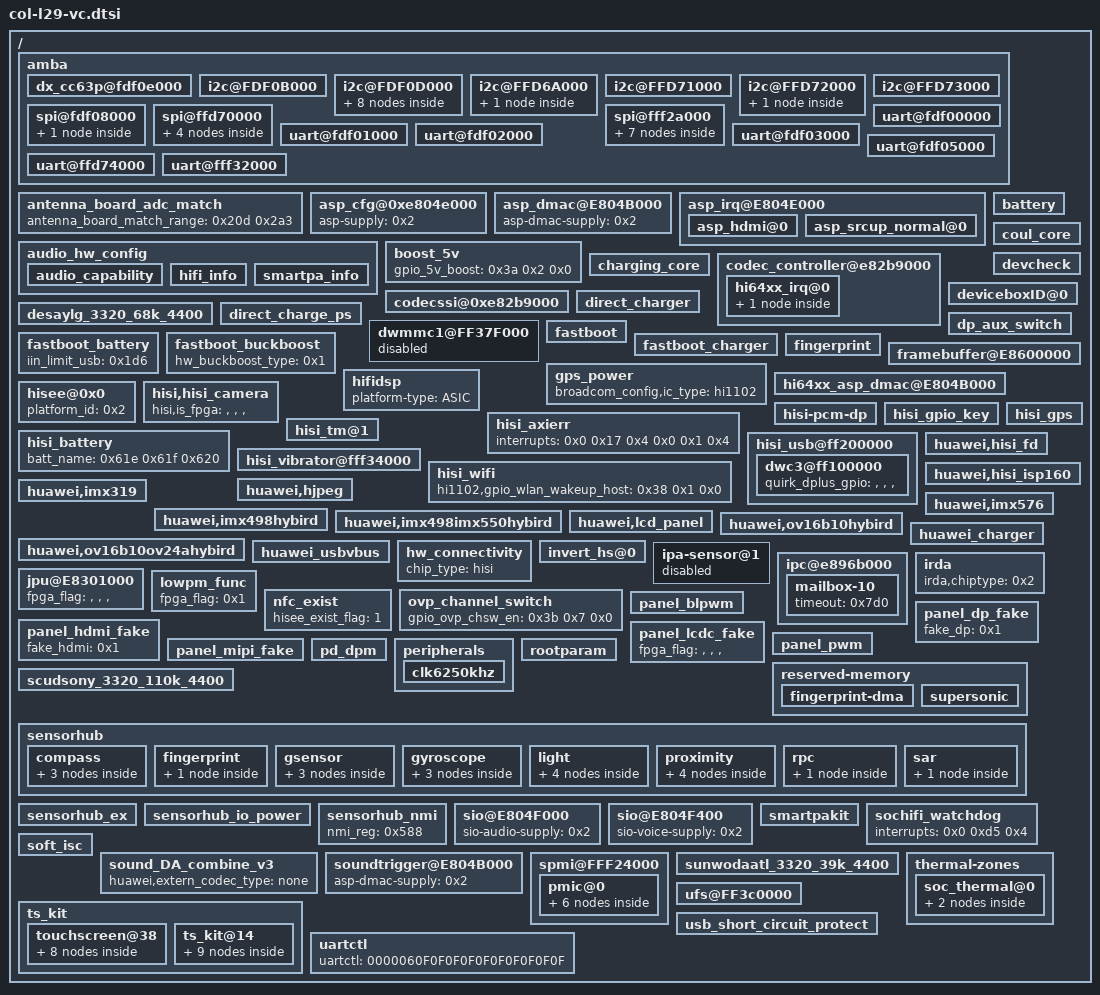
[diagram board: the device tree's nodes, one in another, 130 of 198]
// SPDX-License-Identifier: GPL-2.0
// Editable settings imported from col-l29-vc.dtbo.
/ {
	amba {
		dx_cc63p@fdf0e000 {
			interrupt-parent = <0x1>;
			interrupts = <0x0 0x87 0x4>;
		};
		i2c@FDF0B000 {
			clock-rate = <0x0 0x69db9c0>;
			cs-gpios = <0x232 0x6 0x0 0x232 0x7 0x0>;
			pinctrl-0 = <0x321 0x323 0x409 0x40b>;
			pinctrl-1 = <0x322 0x324 0x40a 0x40c>;
			pinctrl-names = "default", "idle";
		};
		i2c@FDF0D000 {
			ak4376@10 {
				ak4376,hifi_pdn = <0x38 0x7 0x0>;
				ak4376,swtich_existence = "", "", "", "";
				status = "ok";
			};
			huawei,aw3642@7F {
				huawei,flash-chipid = <0x36>;
				huawei,flash-index = "", "", "", "";
				huawei,flash-type = "", "", "", "";
				huawei,flash_current = <0x1f>;
				huawei,slave-address = <0x7f>;
				huawei,torch_current = <0x17>;
			};
			huawei,lm3642@63 {
				huawei,flash-chipid = "", "", "", "";
				huawei,flash-index = "", "", "", "";
				huawei,flash-type = "", "", "", "";
				huawei,flash_current = <0x7>;
				huawei,slave-address = <0x63>;
				huawei,torch_current = <0x2>;
			};
			huawei,mp3331@67 {
				huawei,flash-chipid = <0x18>;
				huawei,flash-index = "", "", "", "";
				huawei,flash-type = "", "", "", "";
				huawei,flash_current = <0x18>;
				huawei,slave-address = <0x67>;
				huawei,torch_current = <0x5>;
			};
			smartpa@4C {
				chip_id = "", "", "", "";
				chip_model = "tas2560";
				chip_vendor = <0x2>;
				compatible = "huawei,smartpakit_i2c";
				dump_regs = <0x0 0x0 0x1 0x0 0x80 0x0 0x0 0x32 0x1 0x0 0x80 0x0 0x0 0x33 0x1 0x0 0x80 0x0 0x0 0x34 0x1 0x0 0x80 0x0>;
				reset_debounce_wait_time = <0x64>;
				version_regs = <0x0 0x0 0x1 0x7d 0x1 0x0>;
				hw_reset {
					ctl_sequence = <0x0 0x3 0x1 0x2>;
					gpio_reset = <0x86>;
				};
				irq_handler {
					gpio_irq = <0xc8>;
					irq_flags = <0x2>;
					need_reset;
					rw_sequence = <0x0 0x14 0x2 0x0 0x0 0x1 0x25 0x1 0x0 0x26 0x1 0x0 0x27 0x1 0x0 0x7 0x1 0x0 0x2a 0x1 0x0>;
				};
				regmap_cfg {
					cache_type = "", "", "", "";
					max_register = <0x80>;
					reg_bits = <0x8>;
					val_bits = <0x8>;
				};
			};
		};
		i2c@FFD6A000 {
			hi6523_charger_i2c6@6B {
				bat_comp = <0x1e>;
				fcp_support = <0x1>;
				gpio_int = <0x5a 0x6 0x0>;
				ico_current_mode = "", "", "", "";
				scp_support = <0x1>;
				vclamp = <0x64>;
			};
		};
		i2c@FFD71000 {
			pinctrl-0;
			pinctrl-1;
			pinctrl-names = "default", "idle";
		};
		i2c@FFD72000 {
			clock-rate = <0x0 0x200b200>;
			cs-gpios = <0x232 0x4 0x0 0x232 0x5 0x0>;
			pinctrl-0 = <0x31d 0x31f 0x405 0x407>;
			pinctrl-1 = <0x31e 0x320 0x406 0x408>;
			pinctrl-names = "default", "idle";
			rt9748@67 {
				loadswitch_en = <0x2a 0x2 0x0>;
				loadswitch_int = <0x2c 0x3 0x0>;
				status = "ok";
			};
		};
		i2c@FFD73000 {
			clock-rate = <0x0 0x200b200>;
			cs-gpios = <0x232 0x6 0x0 0x232 0x7 0x0>;
			pinctrl-0 = <0x321 0x323 0x409 0x40b>;
			pinctrl-1 = <0x322 0x324 0x40a 0x40c>;
			pinctrl-names = "default", "idle";
		};
		spi@fdf08000 {
			clock-rate = <0x124f800>;
			pinctrl-0 = <0x285 0x287 0x289 0x368 0x36a 0x36c>;
			pinctrl-1 = <0x286 0x288 0x28a 0x369 0x36b 0x36d>;
			pinctrl-names = "default", "idle";
			spi_dev10@10 {
				pl022,com-mode = "", "", "", "";
				pl022,ctrl-len = <0x7>;
				pl022,duplex = "", "", "", "";
				pl022,interface = "", "", "", "";
				pl022,rx-level-trig = <0x3>;
				pl022,slave-tx-disable = "", "", "", "";
				pl022,tx-level-trig = <0x3>;
				pl022,wait-state = "", "", "", "";
				reg = "", "", "", "";
				spi-max-frequency = <0x186a0>;
			};
		};
		spi@ffd70000 {
			clock-rate = <0x0 0x802c800>;
			hardware-mutex = <0x1>;
			spi_dev0@0 {
				pl022,com-mode = "", "", "", "";
				pl022,ctrl-len = <0x7>;
				pl022,duplex = "", "", "", "";
				pl022,interface = "", "", "", "";
				pl022,rx-level-trig = <0x3>;
				pl022,slave-tx-disable = "", "", "", "";
				pl022,tx-level-trig = <0x3>;
				pl022,wait-state = "", "", "", "";
				spi-max-frequency = <0x186a0>;
			};
			spi_dev1@1 {
				pl022,com-mode = <0x1>;
				pl022,ctrl-len = <0x7>;
				pl022,duplex = "", "", "", "";
				pl022,interface = "", "", "", "";
				pl022,rx-level-trig = <0x3>;
				pl022,slave-tx-disable = "", "", "", "";
				pl022,tx-level-trig = <0x3>;
				pl022,wait-state = "", "", "", "";
				reg = <0x1>;
				spi-max-frequency = <0xc65d40>;
			};
			spi_dev2@2 {
				pl022,com-mode = <0x2>;
				pl022,ctrl-len = <0x7>;
				pl022,duplex = "", "", "", "";
				pl022,interface = "", "", "", "";
				pl022,rx-level-trig = <0x3>;
				pl022,slave-tx-disable = "", "", "", "";
				pl022,tx-level-trig = <0x3>;
				pl022,wait-state = "", "", "", "";
				reg = <0x2>;
				spi-max-frequency = <0xc65d40>;
			};
			spi_dev3@3 {
				pl022,com-mode = "", "", "", "";
				pl022,ctrl-len = <0x7>;
				pl022,duplex = "", "", "", "";
				pl022,interface = "", "", "", "";
				pl022,rx-level-trig = <0x3>;
				pl022,slave-tx-disable = "", "", "", "";
				pl022,tx-level-trig = <0x3>;
				pl022,wait-state = "", "", "", "";
				reg = <0x3>;
				spi-max-frequency = <0xc65d40>;
			};
		};
		spi@fff2a000 {
			huawei_thp@10 {
				boot_reset_after_delay_ms = "", "", "", "";
				boot_reset_hi_delay_ms = <0x1>;
				boot_reset_low_delay_ms = "", "", "", "";
				cs_gpio = <0x5a 0x3 0x0>;
				irq_gpio = <0x2b 0x4 0x0>;
				pl022,com-mode = <0x2>;
				pl022,ctrl-len = <0x7>;
				pl022,duplex = "", "", "", "";
				pl022,interface = "", "", "", "";
				pl022,rx-level-trig = <0x3>;
				pl022,slave-tx-disable = "", "", "", "";
				pl022,tx-level-trig = <0x3>;
				pl022,wait-state = "", "", "", "";
				reg = "", "", "", "";
				resume_reset_after_delay_ms = <0x1>;
				rst_gpio = <0x50 0x7 0x0>;
				spi-bus-id = <0x3>;
				spi-max-frequency = <0x989680>;
				spi_sync_cs_hi_delay_ns = <0xc8>;
				spi_sync_cs_low_delay_ns = <0xa>;
				suspend_reset_after_delay_ms = "", "", "", "";
				novatech {
					spi_sync_cs_hi_delay_ns = <0xc8>;
					spi_sync_cs_low_delay_ns = <0xc8>;
				};
				thp_input_dev {
					abs_max_x = <0x5a0>;
					abs_max_y = <0xa00>;
					compatible = "huawei,thp_input";
				};
			};
			spi_dev30@30 {
				pl022,com-mode = "", "", "", "";
				pl022,ctrl-len = <0x7>;
				pl022,duplex = "", "", "", "";
				pl022,interface = "", "", "", "";
				pl022,rx-level-trig = <0x3>;
				pl022,slave-tx-disable = "", "", "", "";
				pl022,tx-level-trig = <0x3>;
				pl022,wait-state = "", "", "", "";
				reg = "", "", "", "";
				spi-max-frequency = <0x186a0>;
			};
			spi_dev31@31 {
				pl022,com-mode = <0x1>;
				pl022,ctrl-len = <0x7>;
				pl022,duplex = "", "", "", "";
				pl022,interface = "", "", "", "";
				pl022,rx-level-trig = <0x3>;
				pl022,slave-tx-disable = "", "", "", "";
				pl022,tx-level-trig = <0x3>;
				pl022,wait-state = "", "", "", "";
				reg = <0x1>;
				spi-max-frequency = <0xc65d40>;
			};
			spi_dev32@32 {
				pl022,com-mode = <0x2>;
				pl022,ctrl-len = <0x7>;
				pl022,duplex = "", "", "", "";
				pl022,interface = "", "", "", "";
				pl022,rx-level-trig = <0x3>;
				pl022,slave-tx-disable = "", "", "", "";
				pl022,tx-level-trig = <0x3>;
				pl022,wait-state = "", "", "", "";
				reg = <0x2>;
				spi-max-frequency = <0xc65d40>;
			};
			spi_dev33@33 {
				pl022,com-mode = "", "", "", "";
				pl022,ctrl-len = <0x7>;
				pl022,duplex = "", "", "", "";
				pl022,interface = "", "", "", "";
				pl022,rx-level-trig = <0x3>;
				pl022,slave-tx-disable = "", "", "", "";
				pl022,tx-level-trig = <0x3>;
				pl022,wait-state = "", "", "", "";
				reg = <0x3>;
				spi-max-frequency = <0xc65d40>;
			};
		};
		uart@fdf00000 {
			clock-rate = <0x0 0x69db9c0>;
			pinctrl-0;
			pinctrl-1;
			pinctrl-names = "default", "idle";
			reset-enable-flag = <0x1>;
		};
		uart@fdf01000 {
			clock-rate = <0x0 0x69db9c0>;
			pinctrl-0 = <0x2bf 0x2c1 0x2c3 0x2c5 0x3a2 0x3a4 0x3a6 0x3a8>;
			pinctrl-1 = <0x2c0 0x2c2 0x2c4 0x2c6 0x3a3 0x3a5 0x3a7 0x3a9>;
			pinctrl-names = "default", "idle";
			reset-enable-flag = <0x1>;
		};
		uart@fdf02000 {
			clock-rate = <0x0 0x124f800>;
			dma-names = "", "";
			dmas;
			pinctrl-0 = <0x2b1 0x2b3 0x394 0x396>;
			pinctrl-1 = <0x2b2 0x2b4 0x395 0x397>;
			pinctrl-names = "default", "idle";
		};
		uart@fdf03000 {
			clock-rate = <0x0 0x69db9c0>;
			pinctrl-0;
			pinctrl-1;
			pinctrl-names = "default", "idle";
			reset-enable-flag = <0x1>;
		};
		uart@fdf05000 {
			clock-rate = <0x0 0x69db9c0>;
			pinctrl-0 = <0x2b9 0x3c 0x2bb 0x2bd 0x39c 0x3f 0x39e 0x3a0>;
			pinctrl-1 = <0x2ba 0x41 0x2bc 0x2be 0x39d 0x44 0x39f 0x3a1>;
			pinctrl-names = "default", "idle";
			reset-enable-flag = <0x1>;
		};
		uart@ffd74000 {
			clock-rate = <0x0 0x5f5e100>;
			pinctrl-0;
			pinctrl-1;
			pinctrl-names = "default", "idle";
		};
		uart@fff32000 {
			clock-rate = <0x0 0x124f800>;
			console-fifo-cpuon = <0x3>;
			console-fifo-enable = <0x1>;
			console-fifo-size = <0x40000>;
			pinctrl-0 = <0x2b5 0x2b7 0x398 0x39a>;
			pinctrl-1 = <0x2b6 0x2b8 0x399 0x39b>;
			pinctrl-names = "default", "idle";
		};
	};
	antenna_board_adc_match {
		antenna_board_match_range = <0x20d 0x2a3>;
	};
	asp_cfg@0xe804e000 {
		asp-supply = <0x2>;
	};
	asp_dmac@E804B000 {
		asp-dmac-supply = <0x2>;
	};
	asp_irq@E804E000 {
		asp_hdmi@0 {
			interrupt-names = "asp_irq_hdmi";
			interrupt-parent = <0x254>;
			interrupts = "", "", "", "", "", "", "", "";
		};
		asp_srcup_normal@0 {
			asp-srcup-normal-supply = <0x2>;
			interrupt-names = "asp_srcup_normal";
			interrupt-parent = <0x254>;
			interrupts = <0x1 0x0>;
		};
	};
	audio_hw_config {
		analog_earpiece_enable = "false";
		audio_sar_support = "true";
		codec_dsp_algo = "mad";
		codec_name = "DA_combine_v3";
		cust_name = "audio_custom";
		karaoke_mic_conf_support = "true";
		product_name = "COL-Oversea";
		spk_pa_name = "smartpakit";
		vqm_enable = "true";
		audio_capability {
			lvm_support = "false";
			mmi_capture_enable = "false";
			wakeup_internal_engine = "false";
		};
		hifi_info {
			dynamic_samplerate_support = "false";
			extern_headset_hifi_enable = "false";
			hifi_chip_type = "none";
			highperform_lowpower_support = "false";
		};
		smartpa_info {
			status = "ok";
		};
	};
	battery {
		battery_board_type = <0x2>;
		battery_design_fcc = <0xd48>;
	};
	boost_5v {
		gpio_5v_boost = <0x3a 0x2 0x0>;
		status = "ok";
	};
	charging_core {
		ichg_ac = <0x834>;
		ichg_fcp = <0xd48>;
		iin_fcp = <0x7d0>;
		iin_usb = <0x1d6>;
		inductance_para = "-32767", "15", "2000", "0", "15", "32767", "2000", "0";
		iterm = <0x88>;
		iterm_para = "scudsony", "160";
	};
	codec_controller@e82b9000 {
		gpios = <0x5a 0x4 0x0>;
		pm_runtime_support;
		hi64xx_irq@0 {
			hi6403_codec@0 {
				extern_hs_hifi_ak4376_I2S3 = "", "", "", "";
				hi6421_0x109_reg_change = "", "", "", "";
				hi6421_0x109_xo_freq_codec_val = <0x1>;
				hisilicon,hs_4_pole_min_voltage = <0x384>;
				hisilicon,hs_extern_cable_max_voltage = <0xa8c>;
				hisilicon,hs_extern_cable_min_voltage = <0xa5b>;
				hisilicon,wakeup_audio_algo_support = "", "", "", "";
				hs_detect_extern_cable = <0x1>;
			};
		};
	};
	codecssi@0xe82b9000 {
		status = "ok";
	};
	coul_core {
		adc_batt_id = <0xb>;
		adc_batt_temp = <0xa>;
		current_full_enable = <0x1>;
		iscd_enable = <0x1>;
		last_soc_enable = <0x1>;
		normal_cutoff_vol_mv = <0xbb8>;
		r_coul_mohm = <0x5>;
		r_pcb = "", "", "", "";
		soc_at_term = <0x62>;
	};
	desaylg_3320_68k_4400 {
		fcc_temp = <0xcd0 0xcd0 0xcd0 0xcd0 0xcd0 0xcd0>;
		ifull = <0x12c>;
	};
	devcheck {
		charge = <0x3>;
		charge_loadswitch = <0x3>;
		compass = <0x3>;
		dc_dc = <0x3>;
		g_sensor = <0x3>;
		gyroscope = <0x3>;
		l_sensor = <0x2>;
		nfc = <0x3>;
		touch_panel = <0x2>;
		tps = <0x3>;
	};
	deviceboxID@0 {
		box_num = <0x1>;
		check_mode = "gpio";
		deviceboxID_limit = <0x1f4>;
		enable_boxID = <0x1 0x0 0x0 0x0>;
		gpio_num = <0x1 0x0 0x0 0x0>;
		gpio_speakerID = <0x4b8 0x1 0x0>;
		pinctrl-0 = <0x44d 0x456>;
		pinctrl-1 = <0x44e 0x457>;
		pinctrl-names = "default", "idle";
		speaker_map = <0x1 0x2>;
	};
	direct_charge_ps {
		boost_5v_support_scp_power = <0x1>;
		bst_ctrl = <0x2c 0x4 0x0>;
		bst_ctrl_use_common_gpio = "", "", "", "";
		is_need_bst_ctrl = <0x1>;
	};
	direct_charger {
		cc_cable_detect_enable = <0x1>;
		compensate_r = <0x14>;
		full_path_res_max = <0x1f4>;
		resist_para = "0", "250", "4000", "250", "300", "3000", "300", "500", "2000";
		scp_work_on_charger = <0x1>;
		standard_cable_full_path_res_max = <0x1f4>;
		std_resist_para = "0", "250", "4500", "250", "300", "4000", "300", "500", "3000";
		temp_para = "-32767", "10", "0", "10", "45", "4500", "45", "32767", "0";
		use_5A = <0x1>;
		volt_para = "4100", "4500", "4100", "4250", "4100", "2400", "4380", "2400", "1000";
	};
	dp_aux_switch {
		cs-gpios = <0x50 0x1 0x0 0x50 0x2 0x0>;
		pinctrl-0 = <0x287 0x289 0x36a 0x36c>;
		pinctrl-1 = <0x288 0x28a 0x36b 0x36d>;
		pinctrl-names = "default", "idle";
	};
	dwmmc1@FF37F000 {
		cd-gpio = <0x3a 0x5 0x0>;
		cd-vol = <0x1>;
		cs_sd_timing_config;
		shared-irq = <0x1>;
		status = "disable";
		vmmc-supply = <0x5cc>;
		vqmmc-supply = <0xc9>;
	};
	fastboot {
		gpio-keydown = <0xe6>;
		gpio-keyup = <0xe7>;
		i2c-sel0-gpio = <0x2c>;
		i2c-sel0-val = "", "", "", "";
		i2c-sel1-gpio = <0x2d>;
		i2c-sel1-val = "", "", "", "";
		i2c-select = <0x1>;
		i2c3-pin = "", "", "", "";
		jtagtosd-board-type = <0x1>;
		lpm3-board-type = <0x2>;
		uart-board-type = <0x1>;
	};
	fastboot_battery {
		iin_limit_usb = <0x1d6>;
	};
	fastboot_buckboost {
		hw_buckboost_type = <0x1>;
	};
	fastboot_charger {
		chip_i2c_num = <0x6>;
		hw_charger_type = <0x4>;
	};
	fingerprint {
		fingerprint,cs_gpio = <0xd8>;
		fingerprint,extern_ldo_name = "EXTERN_LDO";
		fingerprint,extern_ldo_num = <0x15>;
		fingerprint,extern_vol = <0x1c3a90>;
		fingerprint,force_storage_type = <0x1>;
		fingerprint,fpc2050 = <0x1>;
		fingerprint,irq_custom_scheme = <0x1>;
		fingerprint,irq_gpio = <0xd3>;
		fingerprint,navigation_adjust1 = <0x1>;
		fingerprint,navigation_adjust2 = <0xb4>;
		fingerprint,product = "columbia";
		fingerprint,reset_gpio = <0xd2>;
		fingerprint,sensor_type = <0x302>;
		fingerprint,spi_num = <0x2>;
		fingerprint,switch_frequence_support = <0x1>;
		fingreprint_ldo-supply = <0x5cf>;
		pinctrl-names = "default", "idle";
		spi-max-frequency = <0x4c4b40>;
	};
	framebuffer@E8600000 {
		dss_version_tag = <0x40>;
		fpga_flag = "", "", "", "";
	};
	gps_power {
		broadcom_config,ic_type = "hi1102";
	};
	hi64xx_asp_dmac@E804B000 {
		asp-dmac-supply = <0x2>;
		interrupt-names = "asp_dma_irq";
		interrupts = <0x0 0xd8 0x4>;
	};
	hifidsp {
		platform-type = "ASIC";
	};
	hisee@0x0 {
		platform_id = <0x2>;
	};
	hisi,hisi_camera {
		hisi,is_fpga = "", "", "", "";
	};
	hisi-pcm-dp {
		dp-pcm-supply = <0x2>;
		interrupt-names = "asp_hdmi_dma";
		interrupts = <0x0 0x96 0x4>;
	};
	hisi_axierr {
		interrupts = <0x0 0x17 0x4 0x0 0x1 0x4>;
	};
	hisi_battery {
		batt_name = <0x61e 0x61f 0x620>;
	};
	hisi_gpio_key {
		gpio-keydown,gpio-irq = <0x5d 0x6 0x0>;
		gpio-keyup,gpio-irq = <0x5d 0x7 0x0>;
		pinctrl-0 = <0x445 0x443>;
		pinctrl-1 = <0x446 0x444>;
		pinctrl-names = "default", "idle";
	};
	hisi_gps {
		clock-names = "ref_clk", "mux_clk", "mdm_clk0", "mdm_clk1", "mdm_clk2";
		clocks = <0x55c 0x161 0x162 0x163 0x164>;
		pinctrl-0 = <0x283 0x366>;
		pinctrl-1 = <0x284 0x367>;
		pinctrl-names = "default", "idle";
	};
	hisi_tm@1 {
		hisi,detect_charger1_tm_chanel = <0x6>;
		hisi,detect_charger1_tm_state = "enable";
		hisi,detect_flash_led_tm_chanel = <0x3>;
		hisi,detect_flash_led_tm_state = "enable";
		hisi,detect_pa_1_tm_state = "disable";
		hisi,peripheral_sensors = <0x8>;
	};
	hisi_usb@ff200000 {
		eye_diagram_host_param = <0x33de7e7>;
		eye_diagram_param = <0x23de7e7>;
		usb_aclk_freq = <0xe2f9780>;
		usb_support_check_voltage = "", "", "", "";
		usb_support_dp = <0x1>;
		dwc3@ff100000 {
			quirk_dplus_gpio = "", "", "", "";
		};
	};
	hisi_vibrator@fff34000 {
		vibrator-vdd-supply = <0x5d4>;
		vibrator_vout_max_voltage = <0x2ab980>;
		vibrator_vout_min_voltage = <0x2ab980>;
	};
	hisi_wifi {
		hi1102,gpio_wlan_wakeup_host = <0x38 0x1 0x0>;
	};
	huawei,hisi_fd {
		clock-low-frequency = <0x1082af40>;
		clock-names = "clk_fd_func";
		clock-value = <0x11e1a300>;
		clocks = <0x5b3>;
		fd-pwr-seq = "fd_regulator", "fd_clk";
		fd_offset_list = <0x418 0x40c 0x410 0x414 0x464 0xfd 0x7a 0x9f 0x58 0x31c 0x470>;
		hisi-fd-supply = <0x1c5>;
		hisi-media-supply = <0x1cd>;
		huawei,smmu-flag = "", "", "", "";
		huawei,top-base = <0xe8304000 0x1000>;
		interrupts = <0x0 0x133 0x4>;
		mstr_offset_list = <0x28 0x34 0x100 0x260 0x3c0>;
		smmu_offset_list = <0x10 0x1c 0x20 0x204 0x20c 0x220 0x224>;
	};
	huawei,hisi_isp160 {
		hisi,is_fpga = "", "", "", "";
		pinctrl-0 = <0x295 0x297 0x299 0x29b 0x29d 0x29f 0x2a1 0x2a3 0x2a5 0x285 0x281 0x44b 0x28f 0x2ad 0x37a 0x37c 0x37e 0x380 0x382 0x384 0x386 0x388 0x38a 0x368 0x364 0x454 0x372 0x390>;
		pinctrl-1 = <0x296 0x298 0x29a 0x29c 0x29e 0x2a0 0x2a2 0x2a4 0x2a6 0x286 0x282 0x44c 0x290 0x2ae 0x37b 0x37d 0x37f 0x381 0x383 0x385 0x387 0x389 0x38b 0x369 0x365 0x455 0x373 0x391>;
		pinctrl-names = "default", "idle";
	};
	huawei,hjpeg {
		clock-low-frequency = <0x1082af40>;
		clock-names = "clk_jpg_func";
		clock-value = <0x21055e80>;
		clocks = <0x237>;
		hjpeg-media-supply = <0x1cd>;
		hjpeg-srt-supply = <0x1c5>;
		huawei,chip_type = <0x1>;
		huawei,cvdr = "", "", "", "", "", "", "", "", "", "", "", "";
		huawei,cvdr-base = <0xe8302000 0x1000>;
		huawei,hjpeg-base = <0xe8300000 0x1000>;
		huawei,power_control = "", "", "", "";
		huawei,smmu-base = <0xe8320000 0x20000>;
		huawei,smmu_type = <0x1>;
		huawei,stream_id = <0x0 0x4 0x5>;
		huawei,subctrl-base = <0xe8304000 0x4>;
		interrupts = <0x0 0x12b 0x4>;
		power-off-frequency = <0xe2f9780>;
		reg = <0x0 0xe8300000 0x0 0x1000>;
	};
	huawei,imx319 {
		avdd-supply = <0x5cb>;
		clock-names = "clk_isp_snclk1";
		clocks = <0x568>;
		dvdd-supply = <0x5d2>;
		gpios = <0x1d7 0x0 0x0>;
		huawei,csi_index = <0x1>;
		huawei,gpio-ctrl-types = "reset";
		huawei,i2c_index = <0x1>;
		huawei,is_fpga = "", "", "", "";
		huawei,ldo-names = "avdd", "dvdd", "iovdd";
		huawei,mclk = <0x16e3600>;
		huawei,pd_valid = <0x1>;
		huawei,reset_valid = <0x1>;
		huawei,sensor_index = <0x1>;
		huawei,sensor_name = "IMX319";
		huawei,vcmpd_valid = "", "", "", "";
		iovdd-supply = <0xc9>;
	};
	huawei,imx498hybird {
		avdd-supply = <0x5d3>;
		avdd2-supply = <0x5cb>;
		clock-names = "clk_isp_snclk0", "clk_isp_snclk2";
		clocks = <0x567 0x569>;
		dvdd-supply = <0x5cd>;
		dvdd2-supply = <0x5ce>;
		gpios = <0x50 0x5 0x0 0x4b8 0x0 0x0>;
		huawei,csi_index = <0x0 0x2>;
		huawei,gpio-ctrl-types = "reset", "reset2";
		huawei,i2c_index = <0x0 0x2>;
		huawei,is_fpga = "", "", "", "";
		huawei,ldo-names = "avdd", "avdd2", "dvdd", "dvdd2", "vcm", "iovdd";
		huawei,mclk = <0x16e3600>;
		huawei,pd_valid = <0x1>;
		huawei,reset_valid = <0x1>;
		huawei,sensor_index = "", "", "", "";
		huawei,sensor_name = "IMX498HYBIRD";
		huawei,vcmpd_valid = "", "", "", "";
		iovdd-supply = <0xc9>;
		module_type = "", "", "", "";
		vcm-supply = <0x5cc>;
	};
	huawei,imx498imx550hybird {
		avdd-supply = <0x5d3>;
		avdd2-supply = <0x5cb>;
		clock-names = "clk_isp_snclk0", "clk_isp_snclk2";
		clocks = <0x567 0x569>;
		dvdd-supply = <0x5cd>;
		dvdd2-supply = <0x5ce>;
		gpios = <0x50 0x5 0x0 0x4b8 0x0 0x0>;
		huawei,csi_index = <0x0 0x2>;
		huawei,gpio-ctrl-types = "reset", "reset2";
		huawei,i2c_index = <0x0 0x2>;
		huawei,is_fpga = "", "", "", "";
		huawei,ldo-names = "avdd", "avdd2", "dvdd", "dvdd2", "vcm", "iovdd";
		huawei,mclk = <0x16e3600>;
		huawei,pd_valid = <0x1>;
		huawei,reset_valid = <0x1>;
		huawei,sensor_index = "", "", "", "";
		huawei,sensor_name = "IMX498IMX550HYBIRD";
		huawei,vcmpd_valid = "", "", "", "";
		iovdd-supply = <0xc9>;
		module_type = "", "", "", "";
		vcm-supply = <0x5cc>;
	};
	huawei,imx576 {
		avdd-supply = <0x5cb>;
		clock-names = "clk_isp_snclk1";
		clocks = <0x568>;
		dvdd-supply = <0x5d2>;
		gpios = <0x1d7 0x0 0x0>;
		huawei,csi_index = <0x1>;
		huawei,gpio-ctrl-types = "reset";
		huawei,i2c_index = <0x1>;
		huawei,is_fpga = "", "", "", "";
		huawei,ldo-names = "avdd", "dvdd", "iovdd";
		huawei,mclk = <0x16e3600>;
		huawei,pd_valid = <0x1>;
		huawei,reset_valid = <0x1>;
		huawei,sensor_index = <0x1>;
		huawei,sensor_name = "IMX576";
		huawei,vcmpd_valid = "", "", "", "";
		iovdd-supply = <0xc9>;
	};
	huawei,lcd_panel {
		lcd-bl-common-ic-support = <0x1>;
		lcd_ldo_channel = <0x2>;
		lcd_ldo_name = "LDO4";
		lcd_ldo_threshold = <0x1388>;
	};
	huawei,ov16b10hybird {
		avdd-supply = <0x5d3>;
		avdd2-supply = <0x5cb>;
		clock-names = "clk_isp_snclk0", "clk_isp_snclk2";
		clocks = <0x567 0x569>;
		dvdd-supply = <0x5cd>;
		dvdd2-supply = <0x5ce>;
		gpios = <0x50 0x5 0x0 0x4b8 0x0 0x0>;
		huawei,csi_index = <0x0 0x2>;
		huawei,gpio-ctrl-types = "reset", "reset2";
		huawei,i2c_index = <0x0 0x2>;
		huawei,is_fpga = "", "", "", "";
		huawei,ldo-names = "avdd", "avdd2", "dvdd", "dvdd2", "vcm", "iovdd";
		huawei,mclk = <0x16e3600>;
		huawei,pd_valid = <0x1>;
		huawei,reset_valid = <0x1>;
		huawei,sensor_index = "", "", "", "";
		huawei,sensor_name = "OV16B10HYBIRD";
		huawei,vcmpd_valid = "", "", "", "";
		iovdd-supply = <0xc9>;
		module_type = "", "", "", "";
		vcm-supply = <0x5cc>;
	};
	huawei,ov16b10ov24ahybird {
		avdd-supply = <0x5d3>;
		avdd2-supply = <0x5cb>;
		clock-names = "clk_isp_snclk0", "clk_isp_snclk2";
		clocks = <0x567 0x569>;
		dvdd-supply = <0x5cd>;
		dvdd2-supply = <0x5ce>;
		gpios = <0x50 0x5 0x0 0x4b8 0x0 0x0>;
		huawei,csi_index = <0x0 0x2>;
		huawei,gpio-ctrl-types = "reset", "reset2";
		huawei,i2c_index = <0x0 0x2>;
		huawei,is_fpga = "", "", "", "";
		huawei,ldo-names = "avdd", "avdd2", "dvdd", "dvdd2", "vcm", "iovdd";
		huawei,mclk = <0x16e3600>;
		huawei,pd_valid = <0x1>;
		huawei,reset_valid = <0x1>;
		huawei,sensor_index = "", "", "", "";
		huawei,sensor_name = "OV16B10OV24AHYBIRD";
		huawei,vcmpd_valid = "", "", "", "";
		iovdd-supply = <0xc9>;
		module_type = "", "", "", "";
		vcm-supply = <0x5cc>;
	};
	huawei_charger {
		fcp_vindpm = <0x1fa4>;
		leak_current_check = <0x1>;
		pd_support = <0x1>;
		support_usb_nonstandard_ico = <0x1>;
	};
	huawei_usbvbus {
		enable_wired_channel = <0x1>;
		pmic_vbus_attach_enable = "", "", "", "";
		pmic_vbus_enable = <0x1>;
	};
	hw_connectivity {
		chip_type = "hisi";
	};
	invert_hs@0 {
		gpio_type = "", "", "", "";
		gpios = "", "", "", "+", "", "", "", "", "", "", "";
		pinctrl-0 = <0x339 0x421>;
		pinctrl-1 = <0x33a 0x422>;
		pinctrl-names = "default", "idle";
	};
	ipa-sensor@1 {
		status = "disabled";
	};
	ipc@e896b000 {
		mailbox-10 {
			timeout = <0x7d0>;
		};
	};
	irda {
		irda,chiptype = <0x2>;
	};
	jpu@E8301000 {
		fpga_flag = "", "", "", "";
	};
	lowpm_func {
		fpga_flag = <0x1>;
	};
	nfc_exist {
		hisee_exist_flag = "1";
	};
	ovp_channel_switch {
		gpio_ovp_chsw_en = <0x3b 0x7 0x0>;
	};
	panel_blpwm {
		#address-cells = <0x2>;
		#size-cells = <0x2>;
		clock-names = "clk_blpwm";
		clocks = <0x5a3>;
		fpga_flag = "", "", "", "";
		pinctrl-0 = <0x315 0x317 0x3fd 0x3ff>;
		pinctrl-1 = <0x316 0x318 0x3fe 0x400>;
		pinctrl-names = "default", "idle";
	};
	panel_dp_fake {
		fake_dp = <0x1>;
	};
	panel_hdmi_fake {
		fake_hdmi = <0x1>;
	};
	panel_lcdc_fake {
		#address-cells = <0x2>;
		#size-cells = <0x2>;
		fpga_flag = "", "", "", "";
	};
	panel_mipi_fake {
		#address-cells = <0x2>;
		#size-cells = <0x2>;
		bl_enable_flag = "", "", "", "";
		fpga_flag = "", "", "", "";
		gpio_nums = <0x22 0x33 0xc>;
		gpios = <0x1d7 0x2 0x0 0x5b 0x3 0x0 0x50 0x4 0x0>;
		lcd-bl-ic-name = "LM36923YFFR";
	};
	panel_pwm {
		#address-cells = <0x2>;
		#size-cells = <0x2>;
		clock-names = "clk_pwm";
		clocks = <0x55b>;
		fpga_flag = "", "", "", "";
	};
	pd_dpm {
		abnormal_cc_detection = <0x1>;
		support_dp = "", "", "", "";
	};
	peripherals {
		clk6250khz {
			#clock-cells = "", "", "", "";
			clock-frequency = <0x601800>;
			clock-output-names = "clk6250khz";
		};
	};
	reserved-memory {
		fingerprint-dma {
			status = "ok";
		};
		supersonic {
			status = "ok";
		};
	};
	rootparam {
		hisi,boardid = <0x6 0x8 0x2 0x3>;
		hisi,boardname = "COL_L29_VC";
		hisi,dtbo_idx = <0x64>;
	};
	scudsony_3320_110k_4400 {
		fcc_temp = <0xcd0 0xcd0 0xcd0 0xcd0 0xcd0 0xcd0>;
		ifull = <0x12c>;
	};
	sensorhub {
		compass {
			mag1 {
				fifoMaxEventCount = "", "", "", "";
				fifoReservedEventCount = "", "", "", "";
				file_id = <0x25>;
				minDelay = <0x2710>;
				sensorlist_name = "mag-akm09911";
				softfilter = <0x2>;
				softiron_parameter = <0xb8 0x28 0x3b 0xff 0xa8 0xff 0x77 0x0 0xad 0x27 0x8e 0xff 0x4f 0x1 0x99 0x0 0x45 0x26 0x0 0x0 0x0 0x0 0x0 0x0 0x0 0x0 0x0>;
				threshold_for_als_calibrate = <0xdac>;
				vendor = "akm";
			};
			mag2 {
				axis_map_x = <0x1>;
				axis_map_y = "", "", "", "";
				axis_map_z = <0x2>;
				bus_number = "", "", "", "";
				calibrate_method = <0x2>;
				chip_id_register = <0x80>;
				chip_id_value = <0x7>;
				fifoMaxEventCount = "", "", "", "";
				fifoReservedEventCount = "", "", "", "";
				file_id = <0x42>;
				gpio_int1 = "", "", "", "7", "", "", "", "", "", "", "";
				gpio_reset = "", "", "", "7", "", "", "", "", "", "", "";
				minDelay = <0x2710>;
				negate_x = "", "", "", "";
				negate_y = "", "", "", "";
				negate_z = <0x1>;
				outbit = "", "", "", "";
				poll_interval = <0xa>;
				reg = <0x2e>;
				sensor_list_info_id = <0x1>;
				sensor_type = "mag";
				sensorlist_name = "mag-yas537";
				softfilter = <0x2>;
				softiron_parameter = <0x10 0x27 0x0 0x0 0x0 0x0 0x0 0x0 0x10 0x27 0x0 0x0 0x0 0x0 0x0 0x0 0x10 0x27 0x0 0x0 0x0 0x0 0x0 0x0 0x0 0x0 0x0>;
				threshold_for_als_calibrate = <0x7d0>;
				vendor = "yamaha";
			};
			mag3 {
				axis_map_x = <0x1>;
				axis_map_y = "", "", "", "";
				axis_map_z = <0x2>;
				bus_number = "", "", "", "";
				calibrate_method = <0x2>;
				chip_id_register = "", "", "", "";
				chip_id_value = <0x48>;
				fifoMaxEventCount = "", "", "", "";
				fifoReservedEventCount = "", "", "", "";
				file_id = <0x43>;
				gpio_int1 = "", "", "", "7", "", "", "", "", "", "", "";
				gpio_reset = "", "", "", "7", "", "", "", "", "", "", "";
				minDelay = <0x2710>;
				negate_x = "", "", "", "";
				negate_y = "", "", "", "";
				negate_z = <0x1>;
				outbit = "", "", "", "";
				poll_interval = <0xa>;
				reg = <0xc>;
				sensor_list_info_id = <0x1>;
				sensor_type = "mag";
				sensorlist_name = "akm-akm09918";
				softiron_parameter = <0xb8 0x28 0x3b 0xff 0xa8 0xff 0x77 0x0 0xad 0x27 0x8e 0xff 0x4f 0x1 0x99 0x0 0x45 0x26 0x0 0x0 0x0 0x0 0x0 0x0 0x0 0x0 0x0>;
				threshold_for_als_calibrate = <0xdac>;
				vendor = "akm";
			};
		};
		fingerprint {
			finger1 {
				bus_number = <0x2>;
				bus_type = <0x1>;
				chip_id_register = <0xaa>;
				chip_id_value = <0x1500>;
				combo_bus_num = <0x2>;
				combo_bus_type = "spi";
				combo_data = <0xd8>;
				combo_rx_exp = [02 15];
				combo_rx_mask = [ff ff];
				combo_tx = [aa];
				file_id = <0x5a>;
				gpio_cs = <0xd8>;
				gpio_irq = <0xd3>;
				gpio_irq_sh = <0x3f6>;
				gpio_reset = <0xd2>;
				gpio_reset_sh = <0x3f5>;
				poll_interval = <0x1f4>;
				product_id_value = <0x24>;
				reg = "", "", "", "";
				sensor_list_info_id = <0x12>;
				sensor_type = "fingerprint";
			};
		};
		gsensor {
			acc1 {
				calibrate_style = "", "", "", "";
				chip_id_register = "", "", "", "";
				chip_id_value = <0xd1>;
				compatible = "huawei,acc_bmi160";
				file_id = <0x21>;
				gpio_int2 = <0x3a 0x7 0x0>;
				gpio_int2_sh = <0x3f2>;
				minDelay = <0xfa0>;
				negate_x = <0x1>;
				negate_z = <0x1>;
				reg = <0x68>;
				sensitivity_x = <0x1>;
				sensitivity_y = <0x1>;
				sensitivity_z = <0x1>;
				sensorlist_name = "accelerometer-bmi160";
				vendor = "bosch";
			};
			acc2 {
				axis_map_x = "", "", "", "";
				axis_map_y = <0x1>;
				axis_map_z = <0x2>;
				bus_number = "", "", "", "";
				calibrate_style = "", "", "", "";
				chip_id_register = <0xf>;
				chip_id_value = <0x69>;
				compatible = "huawei,acc_lsm6ds3";
				device_type = "", "", "", "";
				file_id = <0x22>;
				gpio_int1 = "", "", "", "+", "", "", "", "", "", "", "";
				gpio_int2 = <0x3a 0x7 0x0>;
				gpio_int2_sh = <0x3f2>;
				minDelay = <0xfa0>;
				negate_x = "", "", "", "";
				negate_y = <0x1>;
				negate_z = <0x1>;
				offset_x = "", "", "", "";
				offset_y = "", "", "", "";
				offset_z = "", "", "", "";
				poll_interval = <0xa>;
				reg = <0x6a>;
				sensitivity_x = <0x1>;
				sensitivity_y = <0x1>;
				sensitivity_z = <0x1>;
				sensor_list_info_id = "", "", "", "";
				sensor_type = "acc";
				sensorlist_name = "accelerometer-lsm6ds3";
				vendor = "st";
			};
			acc3 {
				axis_map_x = "", "", "", "";
				axis_map_y = <0x1>;
				axis_map_z = <0x2>;
				bus_number = "", "", "", "";
				calibrate_style = "", "", "", "";
				chip_id_register = <0xf>;
				chip_id_value = <0x6a>;
				compatible = "huawei,acc_lsm6ds3-c";
				device_type = <0x1>;
				file_id = <0x22>;
				gpio_int1 = "", "", "", "+", "", "", "", "", "", "", "";
				gpio_int2 = <0x3a 0x7 0x0>;
				gpio_int2_sh = <0x3f2>;
				minDelay = <0xfa0>;
				negate_x = "", "", "", "";
				negate_y = <0x1>;
				negate_z = <0x1>;
				offset_x = "", "", "", "";
				offset_y = "", "", "", "";
				offset_z = "", "", "", "";
				poll_interval = <0xa>;
				reg = <0x6a>;
				sensitivity_x = <0x1>;
				sensitivity_y = <0x1>;
				sensitivity_z = <0x1>;
				sensor_list_info_id = "", "", "", "";
				sensor_type = "acc";
				sensorlist_name = "accelerometer-lsm6ds3-c";
				vendor = "st";
				wakeup_duration = <0x20>;
			};
		};
		gyroscope {
			gyro1 {
				chip_id_register = "", "", "", "";
				chip_id_value = <0xd1>;
				file_id = <0x23>;
				gpio_int2 = <0x3a 0x7 0x0>;
				gpio_int2_sh = <0x3f2>;
				minDelay = <0xfa0>;
				negate_x = <0x1>;
				negate_z = <0x1>;
				reg = <0x68>;
				sensorlist_name = "gyroscope-bmi160";
				vendor = "bosch";
			};
			gyro2 {
				axis_map_x = "", "", "", "";
				axis_map_y = <0x1>;
				axis_map_z = <0x2>;
				bus_number = "", "", "", "";
				chip_id_register = <0xf>;
				chip_id_value = <0x69>;
				file_id = <0x24>;
				gpio_int1 = <0x2b 0x2 0x0>;
				gpio_int2 = <0x3a 0x7 0x0>;
				gpio_int2_sh = <0x3f2>;
				minDelay = <0xfa0>;
				negate_x = "", "", "", "";
				negate_y = <0x1>;
				negate_z = <0x1>;
				poll_interval = <0xa>;
				reg = <0x6a>;
				sensor_list_info_id = <0x5>;
				sensor_type = "gyro";
				sensorlist_name = "gyroscope-lsm6ds3";
				still_calibrate_threshold = <0x14>;
				vendor = "st";
			};
			gyro3 {
				axis_map_x = "", "", "", "";
				axis_map_y = <0x1>;
				axis_map_z = <0x2>;
				bus_number = "", "", "", "";
				chip_id_register = <0xf>;
				chip_id_value = <0x6a>;
				file_id = <0x24>;
				gpio_int1 = <0x2b 0x2 0x0>;
				gpio_int2 = <0x3a 0x7 0x0>;
				gpio_int2_sh = <0x3f2>;
				minDelay = <0xfa0>;
				negate_x = "", "", "", "";
				negate_y = <0x1>;
				negate_z = <0x1>;
				poll_interval = <0xa>;
				reg = <0x6a>;
				sensor_list_info_id = <0x5>;
				sensor_type = "gyro";
				sensorlist_name = "gyroscope-lsm6ds3-c";
				still_calibrate_threshold = <0x14>;
				vendor = "st";
			};
		};
		light {
			als1 {
				GA1 = <0xca>;
				GA2 = <0xd2>;
				GA3 = <0x2a8>;
				als_extend_data = <0xa 0x0 0x0 0x0 0x0 0x0 0x0 0x0 0x0 0x0 0x0 0x0>;
				als_phone_type = <0x23>;
				als_phone_version = <0xb>;
				chip_id_register = <0x6>;
				chip_id_value = <0xb1>;
				compatible = "huawei,ltr578_als";
				file_id = <0x37>;
				is_cali_supported = <0x1>;
				poll_interval = <0x78>;
				reg = <0x53>;
				sensorlist_name = "light-ltr578";
				vendor = "liteon";
			};
			als2 {
				GA1 = <0xca>;
				GA2 = <0xd2>;
				GA3 = <0x2a8>;
				again = <0x1>;
				als_extend_data = <0x4 0x0 0x0 0x0 0x0 0x0 0x0 0x0 0x0 0x0 0x0 0x0>;
				als_phone_type = <0x23>;
				als_phone_version = <0xb>;
				atime = <0xdb>;
				bus_number = "", "", "", "";
				chip_id_register = <0x6>;
				chip_id_value = <0xb3>;
				compatible = "huawei,apds9922_als";
				file_id = <0x37>;
				init_time = <0x96>;
				is_cali_supported = <0x1>;
				poll_interval = <0x78>;
				reg = <0x53>;
				sensor_list_info_id = <0x3>;
				sensor_type = "als";
				sensorlist_name = "light-apds9922";
				threshold_value = <0x1>;
				tp_color = "", "", "", "";
			};
			als3 {
				GA1 = <0xca>;
				GA2 = <0xd2>;
				GA3 = <0x2a8>;
				again = <0x10>;
				als_extend_data = <0x4 0x0 0x0 0x0 0x0 0x0 0x0 0x0 0x0 0x0 0x0 0x0>;
				als_phone_type = <0x23>;
				als_phone_version = <0xb>;
				atime = <0x64>;
				bus_number = "", "", "", "";
				chip_id_register = <0x92>;
				chip_id_value = <0xe>;
				compatible = "huawei,tmd2745_als";
				file_id = <0x44>;
				init_time = <0x96>;
				is_cali_supported = <0x1>;
				poll_interval = <0x78>;
				reg = <0x39>;
				sensor_list_info_id = <0x3>;
				sensor_type = "als";
				sensorlist_name = "light-tmd2745";
				status = "ok";
				threshold_value = <0x1>;
				tp_color = "", "", "", "";
				vendor = "ams";
			};
			als4 {
				again = <0x1>;
				als_extend_data = <0x2a5b 0x261a 0xec3 0x712 0x1911 0x15c3 0x65d 0x244 0x3e8 0x5f0 0x8fc 0xc1c>;
				als_phone_type = <0x23>;
				als_phone_version = <0xb>;
				atime = <0xdb>;
				bus_number = "", "", "", "";
				chip_id_register = <0x92>;
				chip_id_value = <0xe0>;
				compatible = "huawei,rohm_rpr531_als";
				file_id = <0x46>;
				init_time = <0x96>;
				is_cali_supported = <0x1>;
				poll_interval = <0x78>;
				reg = <0x38>;
				sensor_list_info_id = <0x3>;
				sensor_type = "als";
				status = "ok";
				threshold_value = <0x1>;
				tp_color = "", "", "", "";
			};
		};
		proximity {
			ps1 {
				chip_id_register = <0x6>;
				chip_id_value = <0xb1>;
				compatible = "huawei,ltr578_ps";
				file_id = <0x38>;
				min_proximity_value = <0x352>;
				poll_interval = <0x64>;
				ps_pulse_count = <0x10>;
				pwave_value = <0x25>;
				pwindows_value = <0x36>;
				reg = <0x53>;
				sensorlist_name = "proximity-ltr578";
				threshold_value = <0x3c>;
				use_oily_judge = <0x1>;
				vendor = "liteon";
			};
			ps2 {
				bus_number = "", "", "", "";
				chip_id_register = <0x6>;
				chip_id_value = <0xb3>;
				compatible = "huawei,apds9922_ps";
				file_id = <0x38>;
				init_time = <0x32>;
				min_proximity_value = <0x352>;
				poll_interval = <0x64>;
				ps_pulse_count = <0x8>;
				ptime = <0xff>;
				pwave_value = <0x2b>;
				pwindows_value = <0x48>;
				reg = <0x53>;
				sensor_list_info_id = <0x4>;
				sensor_type = "ps";
				sensorlist_name = "proximity-apds9922";
				threshold_value = <0x23>;
				use_oily_judge = <0x1>;
				vendor = "avago";
			};
			ps3 {
				bus_number = "", "", "", "";
				chip_id_register = <0x92>;
				chip_id_value = <0xe>;
				compatible = "huawei,tmd2745_ps";
				file_id = <0x45>;
				init_time = <0x32>;
				min_proximity_value = <0xb4>;
				poll_interval = <0x64>;
				ps_pulse_count = <0x10>;
				ptime = <0xff>;
				pwave_value = <0x15>;
				pwindows_value = <0x19>;
				reg = <0x39>;
				sensor_list_info_id = <0x4>;
				sensor_type = "ps";
				sensorlist_name = "proximity-tmd2745";
				status = "ok";
				threshold_value = <0x14>;
				use_oily_judge = <0x1>;
				vendor = "ams";
			};
			ps4 {
				bus_number = "", "", "", "";
				chip_id_register = <0x92>;
				chip_id_value = <0xe0>;
				compatible = "huawei,rohm_rpr531_ps";
				file_id = <0x47>;
				init_time = <0x32>;
				max_near_pdata_loop = <0x2>;
				max_oily_add_pdata = <0xfa>;
				min_proximity_value = <0x5dc>;
				oily_count_size = <0xc>;
				oily_max_near_pdata = <0xbb8>;
				poll_interval = <0x64>;
				ps_oily_threshold = <0xc>;
				ps_pulse_count = <0x8>;
				ptime = <0xff>;
				pwave_value = <0x1d>;
				pwindows_value = <0x32>;
				reg = <0x38>;
				sensor_list_info_id = <0x4>;
				sensor_type = "ps";
				status = "ok";
				threshold_value = <0x1b>;
				use_oily_judge = <0x1>;
			};
		};
		rpc {
			rpc {
				compatible = "huawei,rpc";
				default_value = <0x1d>;
				file_id = <0x18>;
				mask = <0xffff 0x23f 0x23f 0x23f 0x23f 0x23f 0x23f 0x23f 0x23f 0x23f 0x23f 0x23f 0x23f 0x23f 0x23f 0x23f 0x23f 0x23f 0x23f 0x23f 0x23f 0x23f 0x20f 0x20f 0x20f 0x20f 0x20f 0x20f 0x20f 0xf 0xffff 0xffff>;
				sensor_list_info_id = <0x18>;
				sensor_type = "rpc";
				sensorlist_name = "rpc";
				status = "ok";
				table = <0xffff 0x217 0x227 0x207 0x213 0x223 0x203 0x214 0x224 0x204 0x215 0x225 0x205 0x216 0x226 0x206 0x211 0x221 0x201 0x212 0x222 0x202 0x1 0x2 0x3 0x4 0x5 0x6 0x7 0x0 0xffff 0xffff>;
			};
		};
		sar {
			sar1 {
				bus_number = "", "", "", "";
				calibrate_order = "0";
				calibrate_type = <0x5>;
				chip_id_register = "", "", "", "";
				chip_id_value = <0xa1 0x50>;
				chip_reg_bit16 = <0x1>;
				compatible = "huawei,adi-adux1050";
				file_id = <0x3a>;
				init_reg_val = <0x10201 0x20530 0x300cc 0x50f11 0x63952 0x70308 0x80200 0x90079 0xa0005 0x798000 0x0 0x0 0x0 0x0 0x0 0xa>;
				poll_interval = <0x64>;
				reg = <0x2c>;
				sensor_list_info_id = <0x14>;
				sensor_type = "cap_prox";
				sensorlist_name = "cap_prox-adux1050";
				shared_flag = "", "", "", "";
				status = "ok";
				to_ap_threshold = [00 c8 00 00 00 00];
				to_modem_threshold = <0x75301388 0xbb806a4 0x12c00c8 0x0 0x0 0x0 0x0 0x0 0x0 0x0 0x0 0x0>;
				vendor = "ADI";
			};
		};
	};
	sensorhub_ex {
		adapt_file_id = <0x8 0x9 0xe 0xf>;
		adapt_sensor_list_id = <0x2 0x6 0x7 0x8 0xb 0xc 0xd 0xe 0xf 0x11 0x12 0x15 0x1d>;
		sensor_1v8_from_pmic = "no";
	};
	sensorhub_io_power {
		need-reset = <0x1>;
		sensor-io-supply = <0x5d0>;
		set-3v = <0x1>;
	};
	sensorhub_nmi {
		nmi_reg = <0x588>;
	};
	sio@E804F000 {
		sio-audio-supply = <0x2>;
	};
	sio@E804F400 {
		sio-voice-supply = <0x2>;
	};
	smartpakit {
		algo_in = "", "", "", "";
		dsp_img_name = "hifi_6403_tas_devkit.img";
		out_device = "", "", "", "";
		soc_platform = "", "", "", "";
		status = "ok";
	};
	sochifi_watchdog {
		interrupts = <0x0 0xd5 0x4>;
	};
	soft_isc {
		fatal_isc_trigger_condition = <0xc350 0x3 0x36d61a35 0x186a0 0x3 0x36d61a35>;
		fatal_isc_trigger_type = <0x1>;
		iscd_chrg_delay_cycles = <0xe>;
		iscd_delay_cycles_enable = <0x1>;
		iscd_file_magic_num = <0x115a3c77>;
	};
	sound_DA_combine_v3 {
		huawei,extern_codec_type = "none";
	};
	soundtrigger@E804B000 {
		asp-dmac-supply = <0x2>;
	};
	spmi@FFF24000 {
		pmic@0 {
			gpios = "", "", "", "]", "", "", "", "", "", "", "";
			hisilicon,pmic_fpga_flag = "", "", "", "";
			pmic_mntn@a0 {
				OCP@217 {
					hisilicon,inacceptable-event = <0x60>;
				};
				OCP@218 {
					hisilicon,inacceptable-event = <0x6f>;
				};
				OCP@219 {
					hisilicon,inacceptable-event = <0x63>;
				};
			};
			sim0 {
				card_tray_style = <0x1>;
				det_debounce_wait_time = <0x12c>;
				hpd_interrupt_to_close_ldo = <0xa>;
				pmu_ldo11_onoff_eco_address = <0x1d>;
				pmu_ldo11_onoff_value = <0x3>;
				pmu_ldo11_vset_address = <0x58>;
				pmu_ldo11_vset_value = <0x1>;
				pmu_ldo12_onoff_eco_address = <0x1e>;
				pmu_ldo12_onoff_value = <0x3>;
				pmu_ldo12_vset_address = <0x59>;
				pmu_ldo12_vset_value = <0x1>;
				pmu_sim_ctrl_address = <0x169>;
				pmu_sim_deb_ctrl_address = <0x16b>;
				pmu_status1_address = <0x7>;
				send_msg_to_cp = <0x1>;
				shared_det_irq = <0x1>;
			};
			sim1 {
				card_tray_style = <0x1>;
				det_debounce_wait_time = <0x12c>;
				hpd_interrupt_to_close_ldo = <0xa>;
				pmu_ldo11_onoff_eco_address = <0x1d>;
				pmu_ldo11_onoff_value = <0x3>;
				pmu_ldo11_vset_address = <0x58>;
				pmu_ldo11_vset_value = <0x1>;
				pmu_ldo12_onoff_eco_address = <0x1e>;
				pmu_ldo12_onoff_value = <0x3>;
				pmu_ldo12_vset_address = <0x59>;
				pmu_ldo12_vset_value = <0x1>;
				pmu_sim_ctrl_address = <0x169>;
				pmu_sim_deb_ctrl_address = <0x16b>;
				pmu_status1_address = <0x7>;
				send_msg_to_cp = <0x1>;
				shared_det_irq = <0x1>;
				status = "ok";
			};
		};
	};
	sunwodaatl_3320_39k_4400 {
		fcc_temp = <0xcd0 0xcd0 0xcd0 0xcd0 0xcd0 0xcd0>;
		ifull = <0x12c>;
	};
	thermal-zones {
		soc_thermal@0 {
			trips {
				trip-point@1 {
					temperature = <0x124f8>;
				};
			};
		};
	};
	ts_kit {
		aft_enable = <0x1>;
		change_game_mode = <0x1>;
		drv_stop_width = "", "", "", "";
		fp_tp_enable = <0x1>;
		lcd_height = "", "", "", "";
		lcd_width = "", "", "", "";
		product = "colu";
		touchscreen@38 {
			aft_wxy_enable = <0x1>;
			enable_edge_touch = <0x1>;
			fts,need_distinguish_lcd = <0x1>;
			fts_edge_data_addr = <0xb7>;
			glove_supported = <0x1>;
			glove_switch_addr = <0xc0>;
			hide_plain_lcd_log = <0x1>;
			holster_supported = <0x1>;
			holster_switch_addr = <0xc1>;
			projectid_length_control_flag = <0x1>;
			roi_pkg_num_addr = <0xcf>;
			roi_supported = <0x1>;
			roi_switch_addr = <0xce>;
			support_get_tp_color = <0x1>;
			touch_switch_flag = <0x2>;
			touch_switch_game_reg = <0x92>;
			AUO {
				compatible = "fts-auo";
				lcd_hide_module_name = "170";
			};
			BOE {
				compatible = "fts-boe";
				lcd_hide_module_name = "130";
			};
			COLU53000 {
				compatible = "fts-COLU53000";
				ic_type = <0x2>;
				lcd_noise_data_test = <0x1>;
				producer = "000";
				provide_panel_id_suppot = <0x1>;
				row_column_delta_test = "", "", "", "";
				row_column_delta_test_point_by_point = <0x1>;
				threshold,in_csv_file = <0x1>;
				threshold,point_by_point_judge = <0x1>;
			};
			COLU53020 {
				compatible = "fts-COLU53020";
				ic_type = <0x2>;
				lcd_noise_data_test = <0x1>;
				producer = "020";
				provide_panel_id_suppot = <0x1>;
				row_column_delta_test = "", "", "", "";
				row_column_delta_test_point_by_point = <0x1>;
				threshold,in_csv_file = <0x1>;
				threshold,point_by_point_judge = <0x1>;
			};
			COLU53040 {
				compatible = "fts-COLU53040";
				ic_type = <0x2>;
				lcd_noise_data_test = <0x1>;
				producer = "040";
				provide_panel_id_suppot = <0x1>;
				row_column_delta_test = "", "", "", "";
				row_column_delta_test_point_by_point = <0x1>;
				threshold,in_csv_file = <0x1>;
				threshold,point_by_point_judge = <0x1>;
			};
			COLU53060 {
				compatible = "fts-COLU53060";
				ic_type = <0x2>;
				lcd_noise_data_test = <0x1>;
				producer = "060";
				provide_panel_id_suppot = <0x1>;
				row_column_delta_test = "", "", "", "";
				row_column_delta_test_point_by_point = <0x1>;
				threshold,in_csv_file = <0x1>;
				threshold,point_by_point_judge = <0x1>;
			};
			CTC {
				compatible = "fts-ctc";
				lcd_hide_module_name = "140";
			};
			TM {
				compatible = "fts-tm";
				lcd_hide_module_name = "110";
			};
		};
		ts_kit@14 {
			fw_only_depend_on_lcd = <0x1>;
			gt1x_edge_add = <0x81a1>;
			gt1x_enable_edge_touch = <0x1>;
			gt1x_roi_data_add = <0xa534>;
			gt1x_roi_fw_supported = "", "", "", "";
			gt1x_support_edge_xyer = <0x1>;
			gt1x_support_wxy = <0x1>;
			gt1x_wxy_data_add = <0xb9b8>;
			hide_plain_lcd_log = <0x1>;
			holster_mode_supported = <0x1>;
			project_id = "COLU54000";
			roi_supported = <0x1>;
			support_get_tp_color = <0x1>;
			touch_switch_flag = <0x2>;
			AUO {
				compatible = "gt1x-auo";
				lcd_hide_module_name = "170";
			};
			BOE {
				compatible = "gt1x-boe";
				lcd_hide_module_name = "130";
			};
			CTC {
				compatible = "gt1x-ctc";
				lcd_hide_module_name = "140";
			};
			JDI {
				compatible = "gt1x-jdi";
				lcd_hide_module_name = "080";
			};
			SENSORID0 {
				module_vendor = "000";
				panel_id = "", "", "", "";
				project_id = "COLU54000";
			};
			SENSORID2 {
				compatible = "gt1x-sensorid-2";
				module_vendor = "060";
				panel_id = <0x6>;
				project_id = "COLU54060";
				provide_panel_id_suppot = <0x1>;
			};
			SENSORID3 {
				compatible = "gt1x-sensorid-3";
				module_vendor = "020";
				panel_id = <0x2>;
				project_id = "COLU54020";
				provide_panel_id_suppot = <0x1>;
			};
			SENSORID4 {
				compatible = "gt1x-sensorid-4";
				module_vendor = "040";
				panel_id = <0x4>;
				project_id = "COLU54040";
				provide_panel_id_suppot = <0x1>;
			};
			TM {
				compatible = "gt1x-tm";
				lcd_hide_module_name = "110";
			};
		};
	};
	uartctl {
		uartctl = "0000060F0F0F0F0F0F0F0F0F0F";
	};
	ufs@FF3c0000 {
		ufs-kirin-broken-clk-gate-bypass;
		ufs-kirin-broken-fastauto;
		ufs-kirin-since-boston-cs;
		ufs-kirin-unipro-termination;
		ufs-kirin-use-HS-GEAR3;
		ufs-kirin-use-rate-B;
	};
	usb_short_circuit_protect {
		close_mosfet_temp = <0xa>;
		interval_switch_temp = <0xf>;
		open_mosfet_temp = <0x14>;
	};
};
